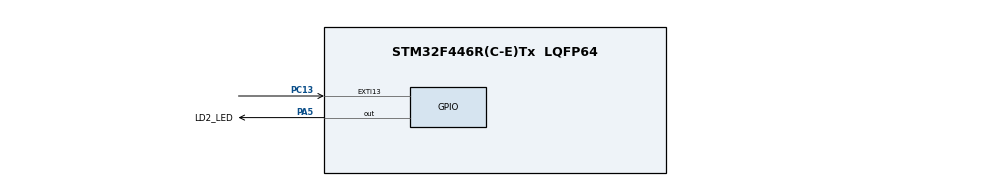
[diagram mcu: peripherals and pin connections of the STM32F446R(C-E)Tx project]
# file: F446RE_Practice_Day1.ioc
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Mcu.Family=STM32F4
Mcu.Name=STM32F446R(C-E)Tx
Mcu.Package=LQFP64
NVIC.EXTI15_10_IRQn=true\:0\:0\:false\:false\:true\:true\:true\:true
NVIC.PriorityGroup=NVIC_PRIORITYGROUP_4
PA13.Mode=Serial_Wire
PA13.Signal=SYS_JTMS-SWDIO
PA14.Mode=Serial_Wire
PA14.Signal=SYS_JTCK-SWCLK
PA5.GPIO_Label=LD2_LED
PA5.Signal=GPIO_Output
PC13.GPIO_ModeDefaultEXTI=GPIO_MODE_IT_FALLING
PC13.Signal=GPXTI13
ProjectManager.HeapSize=0x200
ProjectManager.StackSize=0x400
ProjectManager.TargetToolchain=STM32CubeIDE
RCC.CortexFreq_Value=16000000
RCC.USBFreq_Value=96000000
RCC.VCOOutputFreq_Value=192000000
board=custom

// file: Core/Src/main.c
/* USER CODE BEGIN Header */
/**
  ******************************************************************************
  * @file           : main.c
  * @brief          : Main program body
  ******************************************************************************
  * @attention
  *
  * Copyright (c) 2026 STMicroelectronics.
  * All rights reserved.
  *
  * This software is licensed under terms that can be found in the LICENSE file
  * in the root directory of this software component.
  * If no LICENSE file comes with this software, it is provided AS-IS.
  *
  ******************************************************************************
  */
/* USER CODE END Header */
#include "main.h"

/* USER CODE BEGIN PV */

volatile uint32_t button_press_count = 0;
volatile uint32_t last_button_tick = 0;

/* USER CODE END PV */

void SystemClock_Config(void);
static void MX_GPIO_Init(void);

int main(void)
{

  /* MCU Configuration--------------------------------------------------------*/

  /* Reset of all peripherals, Initializes the Flash interface and the Systick. */
  HAL_Init();

  /* Configure the system clock */
  SystemClock_Config();

  /* Initialize all configured peripherals */
  MX_GPIO_Init();

  /* Infinite loop */
  while (1)
  {

    /* USER CODE BEGIN 3 */

	  /*
	   * CPU 可以在這裡執行其他工作。
	   * 按鍵事件由 EXTI 中斷處理。
	   */

  }
  /* USER CODE END 3 */
}

void SystemClock_Config(void)
{
  RCC_OscInitTypeDef RCC_OscInitStruct = {0};
  RCC_ClkInitTypeDef RCC_ClkInitStruct = {0};

  /** Configure the main internal regulator output voltage
  */
  __HAL_RCC_PWR_CLK_ENABLE();
  __HAL_PWR_VOLTAGESCALING_CONFIG(PWR_REGULATOR_VOLTAGE_SCALE3);

  /** Initializes the RCC Oscillators according to the specified parameters
  * in the RCC_OscInitTypeDef structure.
  */
  RCC_OscInitStruct.OscillatorType = RCC_OSCILLATORTYPE_HSI;
  RCC_OscInitStruct.HSIState = RCC_HSI_ON;
  RCC_OscInitStruct.HSICalibrationValue = RCC_HSICALIBRATION_DEFAULT;
  RCC_OscInitStruct.PLL.PLLState = RCC_PLL_NONE;
  if (HAL_RCC_OscConfig(&RCC_OscInitStruct) != HAL_OK)
  {
    Error_Handler();
  }

  /** Initializes the CPU, AHB and APB buses clocks
  */
  RCC_ClkInitStruct.ClockType = RCC_CLOCKTYPE_HCLK|RCC_CLOCKTYPE_SYSCLK
                              |RCC_CLOCKTYPE_PCLK1|RCC_CLOCKTYPE_PCLK2;
  RCC_ClkInitStruct.SYSCLKSource = RCC_SYSCLKSOURCE_HSI;
  RCC_ClkInitStruct.AHBCLKDivider = RCC_SYSCLK_DIV1;
  RCC_ClkInitStruct.APB1CLKDivider = RCC_HCLK_DIV1;
  RCC_ClkInitStruct.APB2CLKDivider = RCC_HCLK_DIV1;

  if (HAL_RCC_ClockConfig(&RCC_ClkInitStruct, FLASH_LATENCY_0) != HAL_OK)
  {
    Error_Handler();
  }
}

static void MX_GPIO_Init(void)
{
  GPIO_InitTypeDef GPIO_InitStruct = {0};

  /* GPIO Ports Clock Enable */
  __HAL_RCC_GPIOC_CLK_ENABLE();
  __HAL_RCC_GPIOA_CLK_ENABLE();

  /*Configure GPIO pin Output Level */
  HAL_GPIO_WritePin(LD2_LED_GPIO_Port, LD2_LED_Pin, GPIO_PIN_RESET);

  /*Configure GPIO pin : PC13 */
  GPIO_InitStruct.Pin = GPIO_PIN_13;
  GPIO_InitStruct.Mode = GPIO_MODE_IT_FALLING;
  GPIO_InitStruct.Pull = GPIO_NOPULL;
  HAL_GPIO_Init(GPIOC, &GPIO_InitStruct);

  /*Configure GPIO pin : LD2_LED_Pin */
  GPIO_InitStruct.Pin = LD2_LED_Pin;
  GPIO_InitStruct.Mode = GPIO_MODE_OUTPUT_PP;
  GPIO_InitStruct.Pull = GPIO_NOPULL;
  GPIO_InitStruct.Speed = GPIO_SPEED_FREQ_LOW;
  HAL_GPIO_Init(LD2_LED_GPIO_Port, &GPIO_InitStruct);

  /* EXTI interrupt init*/
  HAL_NVIC_SetPriority(EXTI15_10_IRQn, 0, 0);
  HAL_NVIC_EnableIRQ(EXTI15_10_IRQn);

}

/* USER CODE BEGIN 4 */

void HAL_GPIO_EXTI_Callback(uint16_t GPIO_Pin)
{
    if (GPIO_Pin == GPIO_PIN_13)
    {
        uint32_t now = HAL_GetTick();

        /* 簡單按鍵防彈跳：忽略 200 ms 內重複觸發 */
        if ((now - last_button_tick) >= 200U)
        {
            last_button_tick = now;
            button_press_count++;

            HAL_GPIO_TogglePin(GPIOA, GPIO_PIN_5);
        }
    }
}

/* USER CODE END 4 */

void Error_Handler(void)
{
  __disable_irq();
  while (1)
  {
  }
}
